# ATSAMR35J17B device description
Architecture: CORTEX-M0PLUS; Family: SAMR; Series: SAMR35
Registers are 32-bit, read-write, reset 0x0 unless marked. A register's access mark holds for its fields unless they carry their own. Offsets are from the block's base; [hi:lo] are bit positions; {n}, {i} and the like mark numbered series; 'fields as' and 'values as' point back to an identical list; <NAME> marks a mode.

## CCL — Configurable Custom Logic
Instances: CCL 0x43001C00
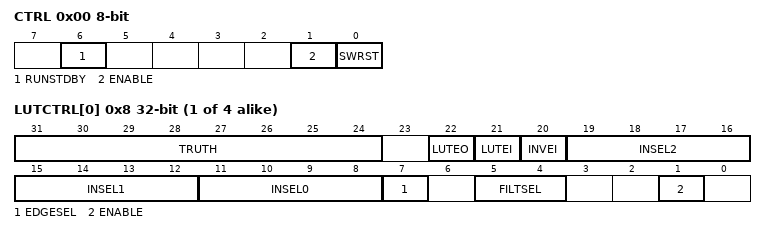
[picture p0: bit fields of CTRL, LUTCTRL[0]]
0x00 CTRL 8-bit — Control
  [6] RUNSTDBY — Run during Standby
  [1] ENABLE
  [0] SWRST — Software Reset
{0x4+i} SEQCTRL[{i}] (i=0..1) 8-bit — SEQ Control x
  [3:0] SEQSEL — Sequential Selection
    0=DISABLE (Sequential logic is disabled); 1=DFF (D flip flop); 2=JK (JK flip flop); 3=LATCH (D latch); 4=RS (RS latch)
{0x8+4i} LUTCTRL[{i}] (i=0..3) — LUT Control x
  [31:24] TRUTH — Truth Value
  [22] LUTEO — Event Output Enable
  [21] LUTEI — Event Input Enable
  [20] INVEI — Input Event Invert
  [19:16] INSEL2 — Input Selection 2
  [15:12] INSEL1 — Input Selection 1
  [11:8] INSEL0 — Input Selection 0
    0=MASK (Masked input); 1=FEEDBACK (Feedback input source); 2=LINK (Linked LUT input source); 3=EVENT (Event in put source); 4=IO (I/O pin input source); 5=AC (AC input source); 6=TC (TC input source); 7=ALTTC (Alternate TC input source); 8=TCC (TCC input source); 9=SERCOM (SERCOM inout source)
  [7] EDGESEL — Edge Selection
  [5:4] FILTSEL — Filter Selection
    0=DISABLE (Filter disabled); 1=SYNCH (Synchronizer enabled); 2=FILTER (Filter enabled)
  [1] ENABLE — LUT Enable

## DAC — Digital-to-Analog Converter
Instances: DAC 0x42003000
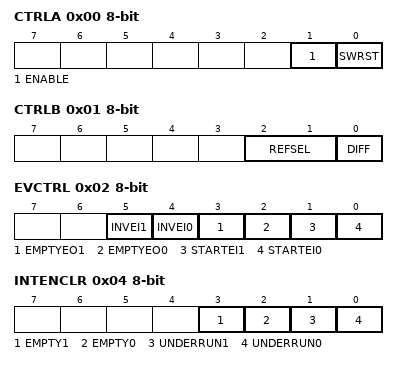
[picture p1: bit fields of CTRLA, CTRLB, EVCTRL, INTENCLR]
0x00 CTRLA 8-bit (WSYNC) — Control A
  [1] ENABLE — Enable DAC Controller
  [0] SWRST — Software Reset
0x01 CTRLB 8-bit — Control B
  [2:1] REFSEL — Reference Selection for DAC0/1
    0=VREFPU (External reference unbuffered); 1=VDDANA (Analog supply); 2=VREFPB (External reference buffered); 3=INTREF (Internal bandgap reference)
  [0] DIFF — Differential mode enable
0x02 EVCTRL 8-bit — Event Control
  [5] INVEI1 — Enable Invertion of DAC 1 input event
  [4] INVEI0 — Enable Invertion of DAC 0 input event
  [3] EMPTYEO1 — Data Buffer Empty Event Output DAC 1
  [2] EMPTYEO0 — Data Buffer Empty Event Output DAC 0
  [1] STARTEI1 — Start Conversion Event Input DAC 1
  [0] STARTEI0 — Start Conversion Event Input DAC 0
0x04 INTENCLR 8-bit (atomic clear) — Interrupt Enable Clear
  [3] EMPTY1 — Data Buffer 1 Empty Interrupt Enable
  [2] EMPTY0 — Data Buffer 0 Empty Interrupt Enable
  [1] UNDERRUN1 — Underrun Interrupt Enable for DAC 1
  [0] UNDERRUN0 — Underrun Interrupt Enable for DAC 0
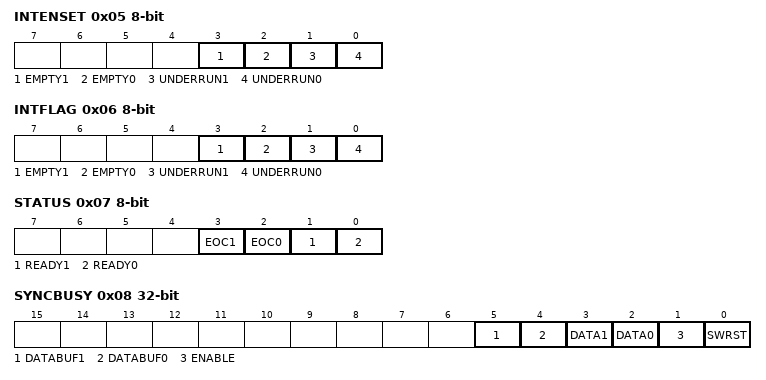
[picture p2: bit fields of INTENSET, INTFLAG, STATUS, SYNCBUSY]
0x05 INTENSET 8-bit (atomic set) — Interrupt Enable Set
  fields as INTENCLR
0x06 INTFLAG 8-bit (atomic clear) — Interrupt Flag Status and Clear
  [3] EMPTY1 — Data Buffer 1 Empty
  [2] EMPTY0 — Data Buffer 0 Empty
  [1] UNDERRUN1 — DAC 1 Underrun
  [0] UNDERRUN0 — DAC 0 Underrun
0x07 STATUS 8-bit ro
  [3] EOC1 — DAC 1 End of Conversion
  [2] EOC0 — DAC 0 End of Conversion
  [1] READY1 — DAC 1 Startup Ready
  [0] READY0 — DAC 0 Startup Ready
0x08 SYNCBUSY ro — Synchronization Busy
  [5] DATABUF1 — Data Buffer DAC 1
  [4] DATABUF0 — Data Buffer DAC 0
  [3] DATA1 — Data DAC 1
  [2] DATA0 — Data DAC 0
  [1] ENABLE — DAC Enable Status
  [0] SWRST — Software Reset
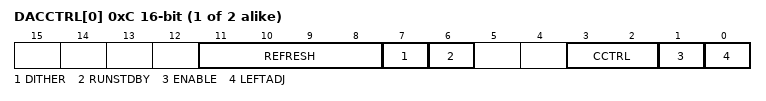
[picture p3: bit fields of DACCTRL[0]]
{0xC+2i} DACCTRL[{i}] (i=0..1) 16-bit — DAC n Control
  [11:8] REFRESH — Refresh period
  [7] DITHER — Dithering Mode
  [6] RUNSTDBY — Run in Standby
  [3:2] CCTRL — Current Control
    0=CC100K (GCLK_DAC <= 1.2MHz (100kSPS)); 1=CC1M (1.2MHz < GCLK_DAC <= 6MHz (500kSPS)); 2=CC12M (6MHz < GCLK_DAC <=12MHz (1MSPS))
  [1] ENABLE — Enable DAC0
  [0] LEFTADJ — Left Adjusted Data
{0x10+2i} DATA[{i}] (i=0..1) 16-bit wo (WSYNC) — DAC n Data
  [15:0] DATA — DAC0 Data
{0x14+2i} DATABUF[{i}] (i=0..1) 16-bit wo (WSYNC) — DAC n Data Buffer
  [15:0] DATABUF — DAC0 Data Buffer
0x18 DBGCTRL 8-bit — Debug Control
  [0] DBGRUN — Debug Run

## DMAC_DESCRIPTOR — Direct Memory Access Controller
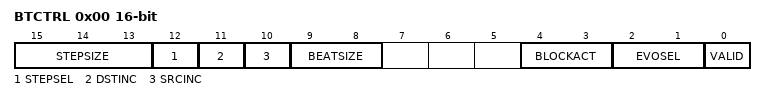
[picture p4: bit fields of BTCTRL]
0x00 BTCTRL 16-bit — Block Transfer Control
  [15:13] STEPSIZE — Address Increment Step Size
    0=Next ADDR = ADDR + (1<<BEATSIZE) * 1; 1=X2 (Next ADDR = ADDR + (1<<BEATSIZE) * 2); 2=X4 (Next ADDR = ADDR + (1<<BEATSIZE) * 4); 3=X8 (Next ADDR = ADDR + (1<<BEATSIZE) * 8); 4=X16 (Next ADDR = ADDR + (1<<BEATSIZE) * 16); 5=X32 (Next ADDR = ADDR + (1<<BEATSIZE) * 32); 6=X64 (Next ADDR = ADDR + (1<<BEATSIZE) * 64); 7=X128 (Next ADDR = ADDR + (1<<BEATSIZE) * 128)
  [12] STEPSEL — Step Selection
    0=DST (Step size settings apply to the destination address); 1=SRC (Step size settings apply to the source address)
  [11] DSTINC — Destination Address Increment Enable
  [10] SRCINC — Source Address Increment Enable
  [9:8] BEATSIZE
    0=BYTE (8-bit bus transfer); 1=HWORD (16-bit bus transfer); 2=WORD (32-bit bus transfer)
  [4:3] BLOCKACT — Block Action
    0=NOACT (Channel will be disabled if it is the last block transfer in the transaction); 1=INT (Channel will be disabled if it is the last block transfer in the transaction and block interrupt); 2=SUSPEND (Channel suspend operation is completed); 3=BOTH (Both channel suspend operation and block interrupt)
  [2:1] EVOSEL — Event Output Selection
    0=DISABLE (Event generation disabled); 1=BLOCK (Event strobe when block transfer complete); 3=BEAT (Event strobe when beat transfer complete)
  [0] VALID — Descriptor Valid
0x02 BTCNT 16-bit reset not defined — Block Transfer Count
0x04 SRCADDR reset not defined — Block Transfer Source Address
  [31:0] SRCADDR — Transfer Source Address
0x08 DSTADDR reset not defined — Block Transfer Destination Address
  [31:0] DSTADDR — Transfer Destination Address
0x0C DESCADDR reset not defined — Next Descriptor Address

## Notices in the file
Copyright (c) 2018 Microchip Technology Inc.
SPDX-License-Identifier: Apache-2.0
Licensed under the Apache License, Version 2.0 (the "License");
you may not use this file except in compliance with the License.
You may obtain a copy of the License at
http://www.apache.org/licenses/LICENSE-2.0
Unless required by applicable law or agreed to in writing, software
distributed under the License is distributed on an "AS IS" BASIS,
WITHOUT WARRANTIES OR CONDITIONS OF ANY KIND, either express or implied.
See the License for the specific language governing permissions and
limitations under the License.
